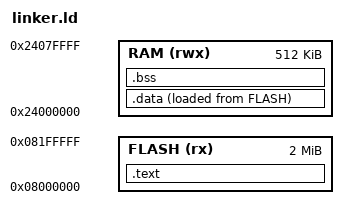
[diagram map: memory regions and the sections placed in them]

MEMORY
{
  FLASH (rx)  : ORIGIN = 0x08000000, LENGTH = 2M
  RAM   (rwx) : ORIGIN = 0x24000000, LENGTH = 512K
}

_estack = ORIGIN(RAM) + LENGTH(RAM);

SECTIONS
{
  .text :
  {
    *(.isr_vector)
    *(.text*)
    *(.rodata*)
  } > FLASH

  .data :
  {
    *(.data*)
  } > RAM AT > FLASH

  .bss :
  {
    *(.bss*)
    *(COMMON)
  } > RAM
}
